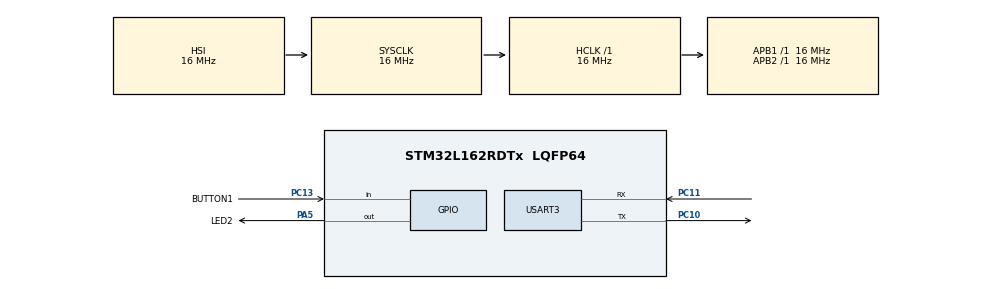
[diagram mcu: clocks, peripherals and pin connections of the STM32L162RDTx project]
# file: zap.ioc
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Dma.AES_IN.2.Direction=DMA_MEMORY_TO_PERIPH
Dma.AES_IN.2.Instance=DMA2_Channel5
Dma.AES_IN.2.MemDataAlignment=DMA_MDATAALIGN_BYTE
Dma.AES_IN.2.MemInc=DMA_MINC_ENABLE
Dma.AES_IN.2.Mode=DMA_NORMAL
Dma.AES_IN.2.PeriphDataAlignment=DMA_PDATAALIGN_BYTE
Dma.AES_IN.2.PeriphInc=DMA_PINC_DISABLE
Dma.AES_IN.2.Priority=DMA_PRIORITY_LOW
Dma.AES_OUT.3.Direction=DMA_PERIPH_TO_MEMORY
Dma.AES_OUT.3.Instance=DMA2_Channel3
Dma.AES_OUT.3.MemDataAlignment=DMA_MDATAALIGN_BYTE
Dma.AES_OUT.3.MemInc=DMA_MINC_ENABLE
Dma.AES_OUT.3.Mode=DMA_NORMAL
Dma.AES_OUT.3.PeriphDataAlignment=DMA_PDATAALIGN_BYTE
Dma.AES_OUT.3.PeriphInc=DMA_PINC_DISABLE
Dma.AES_OUT.3.Priority=DMA_PRIORITY_LOW
Dma.Request0=USART3_RX
Dma.Request1=USART3_TX
Dma.Request2=AES_IN
Dma.Request3=AES_OUT
Dma.USART3_RX.0.Direction=DMA_PERIPH_TO_MEMORY
Dma.USART3_RX.0.Instance=DMA1_Channel3
Dma.USART3_RX.0.MemDataAlignment=DMA_MDATAALIGN_BYTE
Dma.USART3_RX.0.MemInc=DMA_MINC_ENABLE
Dma.USART3_RX.0.Mode=DMA_NORMAL
Dma.USART3_RX.0.PeriphDataAlignment=DMA_PDATAALIGN_BYTE
Dma.USART3_RX.0.PeriphInc=DMA_PINC_DISABLE
Dma.USART3_RX.0.Priority=DMA_PRIORITY_LOW
Dma.USART3_TX.1.Direction=DMA_MEMORY_TO_PERIPH
Dma.USART3_TX.1.Instance=DMA1_Channel2
Dma.USART3_TX.1.MemDataAlignment=DMA_MDATAALIGN_BYTE
Dma.USART3_TX.1.MemInc=DMA_MINC_ENABLE
Dma.USART3_TX.1.Mode=DMA_NORMAL
Dma.USART3_TX.1.PeriphDataAlignment=DMA_PDATAALIGN_BYTE
Dma.USART3_TX.1.PeriphInc=DMA_PINC_DISABLE
Dma.USART3_TX.1.Priority=DMA_PRIORITY_LOW
Mcu.Family=STM32L1
Mcu.Name=STM32L162RDTx
Mcu.Package=LQFP64
NVIC.DMA1_Channel2_IRQn=true\:0\:0\:false\:false\:true
NVIC.DMA1_Channel3_IRQn=true\:0\:0\:false\:false\:true
NVIC.DMA2_Channel3_IRQn=true\:0\:0\:false\:false\:true
NVIC.DMA2_Channel5_IRQn=true\:0\:0\:false\:false\:true
NVIC.PriorityGroup=NVIC_PRIORITYGROUP_4
PA13.Mode=Trace_Asynchronous_SW
PA13.Signal=SYS_JTMS-SWDIO
PA14.Mode=Trace_Asynchronous_SW
PA14.Signal=SYS_JTCK-SWCLK
PA5.GPIO_Label=LED2
PA5.Signal=GPIO_Output
PB3.Mode=Trace_Asynchronous_SW
PB3.Signal=SYS_JTDO-TRACESWO
PC10.Mode=Asynchronous
PC10.Signal=USART3_TX
PC11.Mode=Asynchronous
PC11.Signal=USART3_RX
PC13-WKUP2.GPIO_Label=BUTTON1
PC13-WKUP2.Signal=GPIO_Input
ProjectManager.HeapSize=0x200
ProjectManager.StackSize=0x400
ProjectManager.TargetToolchain=MDK-ARM V5
RCC.AHBFreq_Value=16000000
RCC.APB1Freq_Value=16000000
RCC.APB1TimFreq_Value=16000000
RCC.APB2Freq_Value=16000000
RCC.APB2TimFreq_Value=16000000
RCC.HCLKFreq_Value=16000000
RCC.HSE_VALUE=24000000
RCC.HSI_VALUE=16000000
RCC.LSE_VALUE=32768
RCC.MSI_VALUE=2097000
RCC.SYSCLKFreq_VALUE=16000000
RCC.SYSCLKSource=RCC_SYSCLKSOURCE_HSI
RCC.VCOOutputFreq_Value=48000000
USART3.VirtualMode=VM_ASYNC
VP_AES_VS_AES.Mode=AES_Activate
board=zap

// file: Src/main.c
/**
  ******************************************************************************
  * File Name          : main.c
  * Description        : Main program body
  ******************************************************************************
  ** This notice applies to any and all portions of this file
  * that are not between comment pairs USER CODE BEGIN and
  * USER CODE END. Other portions of this file, whether
  * inserted by the user or by software development tools
  * are owned by their respective copyright owners.
  *
  * COPYRIGHT(c) 2017 STMicroelectronics
  *
  * Redistribution and use in source and binary forms, with or without modification,
  * are permitted provided that the following conditions are met:
  *   1. Redistributions of source code must retain the above copyright notice,
  *      this list of conditions and the following disclaimer.
  *   2. Redistributions in binary form must reproduce the above copyright notice,
  *      this list of conditions and the following disclaimer in the documentation
  *      and/or other materials provided with the distribution.
  *   3. Neither the name of STMicroelectronics nor the names of its contributors
  *      may be used to endorse or promote products derived from this software
  *      without specific prior written permission.
  *
  * THIS SOFTWARE IS PROVIDED BY THE COPYRIGHT HOLDERS AND CONTRIBUTORS "AS IS"
  * AND ANY EXPRESS OR IMPLIED WARRANTIES, INCLUDING, BUT NOT LIMITED TO, THE
  * IMPLIED WARRANTIES OF MERCHANTABILITY AND FITNESS FOR A PARTICULAR PURPOSE ARE
  * DISCLAIMED. IN NO EVENT SHALL THE COPYRIGHT HOLDER OR CONTRIBUTORS BE LIABLE
  * FOR ANY DIRECT, INDIRECT, INCIDENTAL, SPECIAL, EXEMPLARY, OR CONSEQUENTIAL
  * DAMAGES (INCLUDING, BUT NOT LIMITED TO, PROCUREMENT OF SUBSTITUTE GOODS OR
  * SERVICES; LOSS OF USE, DATA, OR PROFITS; OR BUSINESS INTERRUPTION) HOWEVER
  * CAUSED AND ON ANY THEORY OF LIABILITY, WHETHER IN CONTRACT, STRICT LIABILITY,
  * OR TORT (INCLUDING NEGLIGENCE OR OTHERWISE) ARISING IN ANY WAY OUT OF THE USE
  * OF THIS SOFTWARE, EVEN IF ADVISED OF THE POSSIBILITY OF SUCH DAMAGE.
  *
  ******************************************************************************
  */
#include "main.h"
#include "stm32l1xx_hal.h"

CRYP_HandleTypeDef hcryp;
DMA_HandleTypeDef hdma_aes_in;
DMA_HandleTypeDef hdma_aes_out;

UART_HandleTypeDef huart3;
DMA_HandleTypeDef hdma_usart3_rx;
DMA_HandleTypeDef hdma_usart3_tx;

/* USER CODE BEGIN PV */
/* Private variables ---------------------------------------------------------*/

/* USER CODE END PV */

void SystemClock_Config(void);
static void MX_GPIO_Init(void);
static void MX_DMA_Init(void);
static void MX_USART3_UART_Init(void);
static void MX_AES_Init(void);

/* USER CODE BEGIN PFP */
/* Private function prototypes -----------------------------------------------*/

/* USER CODE END PFP */

int main(void)
{

  /* MCU Configuration----------------------------------------------------------*/

  /* Reset of all peripherals, Initializes the Flash interface and the Systick. */
  HAL_Init();

  /* Configure the system clock */
  SystemClock_Config();

  /* Initialize all configured peripherals */
  MX_GPIO_Init();
  MX_DMA_Init();
  MX_USART3_UART_Init();
  MX_AES_Init();

	uint8_t plain[1024];
	uint8_t enc[1024];
  /* USER CODE BEGIN 2 */
	HAL_GPIO_TogglePin(LED2_GPIO_Port, LED2_Pin);

  /* USER CODE END 2 */

  /* Infinite loop */
  while (1)
  {

  /* USER CODE BEGIN 3 */
	HAL_GPIO_TogglePin(LED2_GPIO_Port, LED2_Pin);
	//HAL_CRYP_AESCBC_Encrypt_DMA(&hcryp, plain, 128, enc);
  HAL_CRYP_AESCBC_Encrypt(&hcryp, plain, 128, enc, 1000);
		HAL_Delay(1000);
  }
  /* USER CODE END 3 */

}

/** System Clock Configuration
*/
void SystemClock_Config(void)
{

  RCC_OscInitTypeDef RCC_OscInitStruct;
  RCC_ClkInitTypeDef RCC_ClkInitStruct;

    /**Configure the main internal regulator output voltage
    */
  __HAL_PWR_VOLTAGESCALING_CONFIG(PWR_REGULATOR_VOLTAGE_SCALE1);

    /**Initializes the CPU, AHB and APB busses clocks
    */
  RCC_OscInitStruct.OscillatorType = RCC_OSCILLATORTYPE_HSI;
  RCC_OscInitStruct.HSIState = RCC_HSI_ON;
  RCC_OscInitStruct.HSICalibrationValue = 16;
  RCC_OscInitStruct.PLL.PLLState = RCC_PLL_NONE;
  if (HAL_RCC_OscConfig(&RCC_OscInitStruct) != HAL_OK)
  {
    _Error_Handler(__FILE__, __LINE__);
  }

    /**Initializes the CPU, AHB and APB busses clocks
    */
  RCC_ClkInitStruct.ClockType = RCC_CLOCKTYPE_HCLK|RCC_CLOCKTYPE_SYSCLK
                              |RCC_CLOCKTYPE_PCLK1|RCC_CLOCKTYPE_PCLK2;
  RCC_ClkInitStruct.SYSCLKSource = RCC_SYSCLKSOURCE_HSI;
  RCC_ClkInitStruct.AHBCLKDivider = RCC_SYSCLK_DIV1;
  RCC_ClkInitStruct.APB1CLKDivider = RCC_HCLK_DIV1;
  RCC_ClkInitStruct.APB2CLKDivider = RCC_HCLK_DIV1;

  if (HAL_RCC_ClockConfig(&RCC_ClkInitStruct, FLASH_LATENCY_0) != HAL_OK)
  {
    _Error_Handler(__FILE__, __LINE__);
  }

    /**Configure the Systick interrupt time
    */
  HAL_SYSTICK_Config(HAL_RCC_GetHCLKFreq()/1000);

    /**Configure the Systick
    */
  HAL_SYSTICK_CLKSourceConfig(SYSTICK_CLKSOURCE_HCLK);

  /* SysTick_IRQn interrupt configuration */
  HAL_NVIC_SetPriority(SysTick_IRQn, 0, 0);
}

/* AES init function */
static void MX_AES_Init(void)
{

   uint8_t pKey[16] ;

  hcryp.Instance = AES;
  hcryp.Init.DataType = CRYP_DATATYPE_32B;
  pKey[0] = 0x00;
  pKey[1] = 0x00;
  pKey[2] = 0x00;
  pKey[3] = 0x00;
  pKey[4] = 0x00;
  pKey[5] = 0x00;
  pKey[6] = 0x00;
  pKey[7] = 0x00;
  pKey[8] = 0x00;
  pKey[9] = 0x00;
  pKey[10] = 0x00;
  pKey[11] = 0x00;
  pKey[12] = 0x00;
  pKey[13] = 0x00;
  pKey[14] = 0x00;
  pKey[15] = 0x00;
  hcryp.Init.pKey = &pKey[0];
  if (HAL_CRYP_Init(&hcryp) != HAL_OK)
  {
    _Error_Handler(__FILE__, __LINE__);
  }

}

/* USART3 init function */
static void MX_USART3_UART_Init(void)
{

  huart3.Instance = USART3;
  huart3.Init.BaudRate = 115200;
  huart3.Init.WordLength = UART_WORDLENGTH_8B;
  huart3.Init.StopBits = UART_STOPBITS_1;
  huart3.Init.Parity = UART_PARITY_NONE;
  huart3.Init.Mode = UART_MODE_TX_RX;
  huart3.Init.HwFlowCtl = UART_HWCONTROL_NONE;
  huart3.Init.OverSampling = UART_OVERSAMPLING_16;
  if (HAL_UART_Init(&huart3) != HAL_OK)
  {
    _Error_Handler(__FILE__, __LINE__);
  }

}

static void MX_DMA_Init(void)
{
  /* DMA controller clock enable */
  __HAL_RCC_DMA1_CLK_ENABLE();
  __HAL_RCC_DMA2_CLK_ENABLE();

  /* DMA interrupt init */
  /* DMA1_Channel2_IRQn interrupt configuration */
  HAL_NVIC_SetPriority(DMA1_Channel2_IRQn, 0, 0);
  HAL_NVIC_EnableIRQ(DMA1_Channel2_IRQn);
  /* DMA1_Channel3_IRQn interrupt configuration */
  HAL_NVIC_SetPriority(DMA1_Channel3_IRQn, 0, 0);
  HAL_NVIC_EnableIRQ(DMA1_Channel3_IRQn);
  /* DMA2_Channel3_IRQn interrupt configuration */
  HAL_NVIC_SetPriority(DMA2_Channel3_IRQn, 0, 0);
  HAL_NVIC_EnableIRQ(DMA2_Channel3_IRQn);
  /* DMA2_Channel5_IRQn interrupt configuration */
  HAL_NVIC_SetPriority(DMA2_Channel5_IRQn, 0, 0);
  HAL_NVIC_EnableIRQ(DMA2_Channel5_IRQn);

}

/** Configure pins as
        * Analog
        * Input
        * Output
        * EVENT_OUT
        * EXTI
*/
static void MX_GPIO_Init(void)
{

  GPIO_InitTypeDef GPIO_InitStruct;

  /* GPIO Ports Clock Enable */
  __HAL_RCC_GPIOC_CLK_ENABLE();
  __HAL_RCC_GPIOA_CLK_ENABLE();
  __HAL_RCC_GPIOB_CLK_ENABLE();

  /*Configure GPIO pin Output Level */
  HAL_GPIO_WritePin(LED2_GPIO_Port, LED2_Pin, GPIO_PIN_RESET);

  /*Configure GPIO pin : BUTTON1_Pin */
  GPIO_InitStruct.Pin = BUTTON1_Pin;
  GPIO_InitStruct.Mode = GPIO_MODE_INPUT;
  GPIO_InitStruct.Pull = GPIO_NOPULL;
  HAL_GPIO_Init(BUTTON1_GPIO_Port, &GPIO_InitStruct);

  /*Configure GPIO pin : LED2_Pin */
  GPIO_InitStruct.Pin = LED2_Pin;
  GPIO_InitStruct.Mode = GPIO_MODE_OUTPUT_PP;
  GPIO_InitStruct.Pull = GPIO_NOPULL;
  GPIO_InitStruct.Speed = GPIO_SPEED_FREQ_LOW;
  HAL_GPIO_Init(LED2_GPIO_Port, &GPIO_InitStruct);

}

void _Error_Handler(char * file, int line)
{
  while(1)
  {
  }
}

/************************ (C) COPYRIGHT STMicroelectronics *****END OF FILE****/
